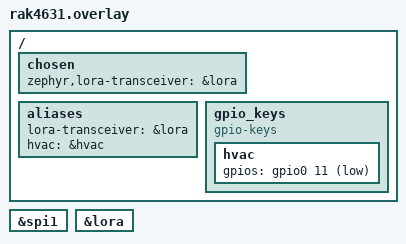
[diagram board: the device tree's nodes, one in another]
#include <zephyr/dt-bindings/gpio/gpio.h>

/ {
	chosen {
		zephyr,lora-transceiver = &lora;
	};

	aliases {
		lora-transceiver = &lora;
		hvac = &hvac;
	};

	gpio_keys: gpio_keys {
		compatible = "gpio-keys";
		hvac: hvac {
			gpios = <&gpio0 11 (GPIO_ACTIVE_LOW | GPIO_PULL_UP)>;
		};
	};
};

arduino_spi: &spi1 {
};

lora_semtech_sx126xmb2xxs: &lora {
};
